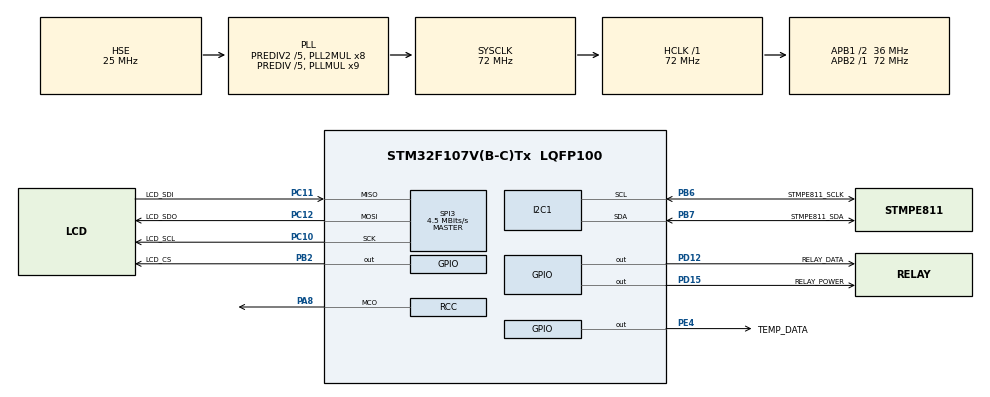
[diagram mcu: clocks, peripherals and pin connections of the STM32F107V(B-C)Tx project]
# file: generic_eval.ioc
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I2C1.I2C_Mode=I2C_Fast
Mcu.Family=STM32F1
Mcu.Name=STM32F107V(B-C)Tx
Mcu.Package=LQFP100
NVIC.PriorityGroup=NVIC_PRIORITYGROUP_4
NVIC.RTC_IRQn=true\:0\:0\:false\:false\:true\:true
NVIC.TIM2_IRQn=true\:5\:0\:true\:false\:true\:true
OSC_IN.Mode=HSE-External-Oscillator
OSC_IN.Signal=RCC_OSC_IN
OSC_OUT.Mode=HSE-External-Oscillator
OSC_OUT.Signal=RCC_OSC_OUT
PA13.Mode=Serial_Wire
PA13.Signal=SYS_JTMS-SWDIO
PA14.Mode=Serial_Wire
PA14.Signal=SYS_JTCK-SWCLK
PA8.Mode=Clock-out
PA8.Signal=RCC_MCO
PB2.GPIO_Label=LCD_CS
PB2.Signal=GPIO_Output
PB6.GPIO_Label=STMPE811_SCLK
PB6.GPIO_Speed=GPIO_SPEED_FREQ_LOW
PB6.Mode=I2C
PB6.Signal=I2C1_SCL
PB7.GPIO_Label=STMPE811_SDA
PB7.GPIO_Speed=GPIO_SPEED_FREQ_LOW
PB7.Mode=I2C
PB7.Signal=I2C1_SDA
PC10.GPIO_Label=LCD_SCL
PC10.Mode=Full_Duplex_Master
PC10.Signal=SPI3_SCK
PC11.GPIO_Label=LCD_SDI
PC11.Mode=Full_Duplex_Master
PC11.Signal=SPI3_MISO
PC12.GPIO_Label=LCD_SDO
PC12.Mode=Full_Duplex_Master
PC12.Signal=SPI3_MOSI
PC14-OSC32_IN.Mode=LSE-External-Oscillator
PC14-OSC32_IN.Signal=RCC_OSC32_IN
PC15-OSC32_OUT.Mode=LSE-External-Oscillator
PC15-OSC32_OUT.Signal=RCC_OSC32_OUT
PD12.GPIO_Label=RELAY_DATA
PD12.GPIO_Speed=GPIO_SPEED_FREQ_MEDIUM
PD12.Signal=GPIO_Output
PD15.GPIO_Label=RELAY_POWER
PD15.GPIO_Speed=GPIO_SPEED_FREQ_MEDIUM
PD15.PinState=GPIO_PIN_SET
PD15.Signal=GPIO_Output
PE4.GPIO_Label=TEMP_DATA
PE4.GPIO_ModeDefaultOutputPP=GPIO_MODE_OUTPUT_PP
PE4.GPIO_Speed=GPIO_SPEED_FREQ_MEDIUM
PE4.Signal=GPIO_Output
ProjectManager.HeapSize=0x200
ProjectManager.StackSize=0x400
ProjectManager.TargetToolchain=Makefile
RCC.AHBFreq_Value=72000000
RCC.APB1CLKDivider=RCC_HCLK_DIV2
RCC.APB1Freq_Value=36000000
RCC.APB1TimFreq_Value=72000000
RCC.APB2Freq_Value=72000000
RCC.APB2TimFreq_Value=72000000
RCC.HCLKFreq_Value=72000000
RCC.HSEDivPLL=RCC_HSE_PREDIV_DIV5
RCC.HSE_VALUE=25000000
RCC.PLLMUL=RCC_PLL_MUL9
RCC.PLLSourceVirtual=RCC_PLLSOURCE_HSE
RCC.Prediv1Source=RCC_PREDIV1_SOURCE_PLL2
RCC.Prediv2=RCC_HSE_PREDIV2_DIV5
RCC.RCC_MCOSource=RCC_MCO1SOURCE_HSE
RCC.RTCClockSelection=RCC_RTCCLKSOURCE_LSE
RCC.SYSCLKFreq_VALUE=72000000
RCC.SYSCLKSource=RCC_SYSCLKSOURCE_PLLCLK
RCC.USBFreq_Value=48000000
RTC.AutoPrediv=RTC_AUTO_1_SECOND
RTC.Format=RTC_FORMAT_BCD
RTC.OutPut=RTC_OUTPUTSOURCE_SECOND
SPI3.BaudRatePrescaler=SPI_BAUDRATEPRESCALER_8
SPI3.CLKPhase=SPI_PHASE_2EDGE
SPI3.CLKPolarity=SPI_POLARITY_HIGH
SPI3.CRCCalculation=SPI_CRCCALCULATION_DISABLE
SPI3.CalculateBaudRate=4.5 MBits/s
SPI3.Direction=SPI_DIRECTION_2LINES
SPI3.Mode=SPI_MODE_MASTER
SPI3.VirtualType=VM_MASTER
TIM2.Period=200
TIM2.Prescaler=36000
TIM2.TIM_MasterOutputTrigger=TIM_TRGO_RESET
VP_RTC_VS_RTC_Activate.Mode=RTC_Enabled
VP_TIM2_VS_ClockSourceINT.Mode=Internal
board=generic_eval

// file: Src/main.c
/**
  ******************************************************************************
  * @file           : main.c
  * @brief          : Main program body
  ******************************************************************************
  ** This notice applies to any and all portions of this file
  * that are not between comment pairs USER CODE BEGIN and
  * USER CODE END. Other portions of this file, whether
  * inserted by the user or by software development tools
  * are owned by their respective copyright owners.
  *
  * COPYRIGHT(c) 2018 STMicroelectronics
  *
  * Redistribution and use in source and binary forms, with or without modification,
  * are permitted provided that the following conditions are met:
  *   1. Redistributions of source code must retain the above copyright notice,
  *      this list of conditions and the following disclaimer.
  *   2. Redistributions in binary form must reproduce the above copyright notice,
  *      this list of conditions and the following disclaimer in the documentation
  *      and/or other materials provided with the distribution.
  *   3. Neither the name of STMicroelectronics nor the names of its contributors
  *      may be used to endorse or promote products derived from this software
  *      without specific prior written permission.
  *
  * THIS SOFTWARE IS PROVIDED BY THE COPYRIGHT HOLDERS AND CONTRIBUTORS "AS IS"
  * AND ANY EXPRESS OR IMPLIED WARRANTIES, INCLUDING, BUT NOT LIMITED TO, THE
  * IMPLIED WARRANTIES OF MERCHANTABILITY AND FITNESS FOR A PARTICULAR PURPOSE ARE
  * DISCLAIMED. IN NO EVENT SHALL THE COPYRIGHT HOLDER OR CONTRIBUTORS BE LIABLE
  * FOR ANY DIRECT, INDIRECT, INCIDENTAL, SPECIAL, EXEMPLARY, OR CONSEQUENTIAL
  * DAMAGES (INCLUDING, BUT NOT LIMITED TO, PROCUREMENT OF SUBSTITUTE GOODS OR
  * SERVICES; LOSS OF USE, DATA, OR PROFITS; OR BUSINESS INTERRUPTION) HOWEVER
  * CAUSED AND ON ANY THEORY OF LIABILITY, WHETHER IN CONTRACT, STRICT LIABILITY,
  * OR TORT (INCLUDING NEGLIGENCE OR OTHERWISE) ARISING IN ANY WAY OUT OF THE USE
  * OF THIS SOFTWARE, EVEN IF ADVISED OF THE POSSIBILITY OF SUCH DAMAGE.
  *
  ******************************************************************************
  */
#include "main.h"
#include "stm32f1xx_hal.h"

/* USER CODE BEGIN Includes */
#include "stm3210c_eval.h" // For BSP_LED_Init
/* USER CODE END Includes */

I2C_HandleTypeDef hi2c1;

RTC_HandleTypeDef hrtc;

SPI_HandleTypeDef hspi3;

TIM_HandleTypeDef htim2;

/* USER CODE BEGIN PV */
/* Private variables ---------------------------------------------------------*/

/* USER CODE END PV */

void SystemClock_Config(void);
static void MX_GPIO_Init(void);
static void MX_RTC_Init(void);
static void MX_I2C1_Init(void);
static void MX_SPI3_Init(void);
static void MX_TIM2_Init(void);

/* USER CODE BEGIN PFP */
/* Private function prototypes -----------------------------------------------*/

/* USER CODE END PFP */

/* USER CODE BEGIN 0 */
#if 0
/* USER CODE END 0 */

int main(void)
{
  /* USER CODE BEGIN 1 */
#endif
int cube_main(void)
{
  /* USER CODE END 1 */

  /* MCU Configuration----------------------------------------------------------*/

  /* Reset of all peripherals, Initializes the Flash interface and the Systick. */
  HAL_Init();

  /* Configure the system clock */
  SystemClock_Config();

  /* Initialize all configured peripherals */
  MX_GPIO_Init();
  MX_RTC_Init();
  MX_I2C1_Init();
  MX_SPI3_Init();
  MX_TIM2_Init();
  /* USER CODE BEGIN 2 */
  HAL_RTCEx_SetSecond_IT(&hrtc);
  /* USER CODE END 2 */

  /* Infinite loop */

}

void SystemClock_Config(void)
{

  RCC_OscInitTypeDef RCC_OscInitStruct;
  RCC_ClkInitTypeDef RCC_ClkInitStruct;
  RCC_PeriphCLKInitTypeDef PeriphClkInit;

    /**Initializes the CPU, AHB and APB busses clocks
    */
  RCC_OscInitStruct.OscillatorType = RCC_OSCILLATORTYPE_HSE|RCC_OSCILLATORTYPE_LSE;
  RCC_OscInitStruct.HSEState = RCC_HSE_ON;
  RCC_OscInitStruct.HSEPredivValue = RCC_HSE_PREDIV_DIV5;
  RCC_OscInitStruct.LSEState = RCC_LSE_ON;
  RCC_OscInitStruct.HSIState = RCC_HSI_ON;
  RCC_OscInitStruct.Prediv1Source = RCC_PREDIV1_SOURCE_PLL2;
  RCC_OscInitStruct.PLL.PLLState = RCC_PLL_ON;
  RCC_OscInitStruct.PLL.PLLSource = RCC_PLLSOURCE_HSE;
  RCC_OscInitStruct.PLL.PLLMUL = RCC_PLL_MUL9;
  RCC_OscInitStruct.PLL2.PLL2State = RCC_PLL2_ON;
  RCC_OscInitStruct.PLL2.PLL2MUL = RCC_PLL2_MUL8;
  RCC_OscInitStruct.PLL2.HSEPrediv2Value = RCC_HSE_PREDIV2_DIV5;
  if (HAL_RCC_OscConfig(&RCC_OscInitStruct) != HAL_OK)
  {
    _Error_Handler(__FILE__, __LINE__);
  }

    /**Initializes the CPU, AHB and APB busses clocks
    */
  RCC_ClkInitStruct.ClockType = RCC_CLOCKTYPE_HCLK|RCC_CLOCKTYPE_SYSCLK
                              |RCC_CLOCKTYPE_PCLK1|RCC_CLOCKTYPE_PCLK2;
  RCC_ClkInitStruct.SYSCLKSource = RCC_SYSCLKSOURCE_PLLCLK;
  RCC_ClkInitStruct.AHBCLKDivider = RCC_SYSCLK_DIV1;
  RCC_ClkInitStruct.APB1CLKDivider = RCC_HCLK_DIV2;
  RCC_ClkInitStruct.APB2CLKDivider = RCC_HCLK_DIV1;

  if (HAL_RCC_ClockConfig(&RCC_ClkInitStruct, FLASH_LATENCY_2) != HAL_OK)
  {
    _Error_Handler(__FILE__, __LINE__);
  }

  PeriphClkInit.PeriphClockSelection = RCC_PERIPHCLK_RTC;
  PeriphClkInit.RTCClockSelection = RCC_RTCCLKSOURCE_LSE;
  if (HAL_RCCEx_PeriphCLKConfig(&PeriphClkInit) != HAL_OK)
  {
    _Error_Handler(__FILE__, __LINE__);
  }

  HAL_RCC_MCOConfig(RCC_MCO, RCC_MCO1SOURCE_HSE, RCC_MCODIV_1);

    /**Configure the Systick interrupt time
    */
  HAL_SYSTICK_Config(HAL_RCC_GetHCLKFreq()/1000);

    /**Configure the Systick
    */
  HAL_SYSTICK_CLKSourceConfig(SYSTICK_CLKSOURCE_HCLK);

    /**Configure the Systick interrupt time
    */
  __HAL_RCC_PLLI2S_ENABLE();

  /* SysTick_IRQn interrupt configuration */
  HAL_NVIC_SetPriority(SysTick_IRQn, 0, 0);
}

/* I2C1 init function */
static void MX_I2C1_Init(void)
{

  hi2c1.Instance = I2C1;
  hi2c1.Init.ClockSpeed = 400000;
  hi2c1.Init.DutyCycle = I2C_DUTYCYCLE_2;
  hi2c1.Init.OwnAddress1 = 0;
  hi2c1.Init.AddressingMode = I2C_ADDRESSINGMODE_7BIT;
  hi2c1.Init.DualAddressMode = I2C_DUALADDRESS_DISABLE;
  hi2c1.Init.OwnAddress2 = 0;
  hi2c1.Init.GeneralCallMode = I2C_GENERALCALL_DISABLE;
  hi2c1.Init.NoStretchMode = I2C_NOSTRETCH_DISABLE;
  if (HAL_I2C_Init(&hi2c1) != HAL_OK)
  {
    _Error_Handler(__FILE__, __LINE__);
  }

}

/* RTC init function */
static void MX_RTC_Init(void)
{

    /**Initialize RTC Only
    */
  hrtc.Instance = RTC;
  hrtc.Init.AsynchPrediv = RTC_AUTO_1_SECOND;
  hrtc.Init.OutPut = RTC_OUTPUTSOURCE_SECOND;
  if (HAL_RTC_Init(&hrtc) != HAL_OK)
  {
    _Error_Handler(__FILE__, __LINE__);
  }

}

/* SPI3 init function */
static void MX_SPI3_Init(void)
{

  /* SPI3 parameter configuration*/
  hspi3.Instance = SPI3;
  hspi3.Init.Mode = SPI_MODE_MASTER;
  hspi3.Init.Direction = SPI_DIRECTION_2LINES;
  hspi3.Init.DataSize = SPI_DATASIZE_8BIT;
  hspi3.Init.CLKPolarity = SPI_POLARITY_HIGH;
  hspi3.Init.CLKPhase = SPI_PHASE_2EDGE;
  hspi3.Init.NSS = SPI_NSS_SOFT;
  hspi3.Init.BaudRatePrescaler = SPI_BAUDRATEPRESCALER_8;
  hspi3.Init.FirstBit = SPI_FIRSTBIT_MSB;
  hspi3.Init.TIMode = SPI_TIMODE_DISABLE;
  hspi3.Init.CRCCalculation = SPI_CRCCALCULATION_DISABLE;
  hspi3.Init.CRCPolynomial = 10;
  if (HAL_SPI_Init(&hspi3) != HAL_OK)
  {
    _Error_Handler(__FILE__, __LINE__);
  }

}

/* TIM2 init function */
static void MX_TIM2_Init(void)
{

  TIM_ClockConfigTypeDef sClockSourceConfig;
  TIM_MasterConfigTypeDef sMasterConfig;

  htim2.Instance = TIM2;
  htim2.Init.Prescaler = 36000;
  htim2.Init.CounterMode = TIM_COUNTERMODE_UP;
  htim2.Init.Period = 200;
  htim2.Init.ClockDivision = TIM_CLOCKDIVISION_DIV1;
  //htim2.Init.AutoReloadPreload = TIM_AUTORELOAD_PRELOAD_DISABLE;
  if (HAL_TIM_Base_Init(&htim2) != HAL_OK)
  {
    _Error_Handler(__FILE__, __LINE__);
  }

  sClockSourceConfig.ClockSource = TIM_CLOCKSOURCE_INTERNAL;
  if (HAL_TIM_ConfigClockSource(&htim2, &sClockSourceConfig) != HAL_OK)
  {
    _Error_Handler(__FILE__, __LINE__);
  }

  sMasterConfig.MasterOutputTrigger = TIM_TRGO_RESET;
  sMasterConfig.MasterSlaveMode = TIM_MASTERSLAVEMODE_DISABLE;
  if (HAL_TIMEx_MasterConfigSynchronization(&htim2, &sMasterConfig) != HAL_OK)
  {
    _Error_Handler(__FILE__, __LINE__);
  }

}

/** Configure pins as
        * Analog
        * Input
        * Output
        * EVENT_OUT
        * EXTI
     PA8   ------> RCC_MCO
*/
static void MX_GPIO_Init(void)
{

  GPIO_InitTypeDef GPIO_InitStruct;

  /* GPIO Ports Clock Enable */
  __HAL_RCC_GPIOE_CLK_ENABLE();
  __HAL_RCC_GPIOC_CLK_ENABLE();
  __HAL_RCC_GPIOA_CLK_ENABLE();
  __HAL_RCC_GPIOB_CLK_ENABLE();
  __HAL_RCC_GPIOD_CLK_ENABLE();

  /*Configure GPIO pin Output Level */
  HAL_GPIO_WritePin(TEMP_DATA_GPIO_Port, TEMP_DATA_Pin, GPIO_PIN_RESET);

  /*Configure GPIO pin Output Level */
  HAL_GPIO_WritePin(LCD_CS_GPIO_Port, LCD_CS_Pin, GPIO_PIN_RESET);

  /*Configure GPIO pin Output Level */
  HAL_GPIO_WritePin(RELAY_DATA_GPIO_Port, RELAY_DATA_Pin, GPIO_PIN_RESET);

  /*Configure GPIO pin Output Level */
  HAL_GPIO_WritePin(RELAY_POWER_GPIO_Port, RELAY_POWER_Pin, GPIO_PIN_SET);

  /*Configure GPIO pin : TEMP_DATA_Pin */
  GPIO_InitStruct.Pin = TEMP_DATA_Pin;
  GPIO_InitStruct.Mode = GPIO_MODE_OUTPUT_PP;
  GPIO_InitStruct.Speed = GPIO_SPEED_FREQ_MEDIUM;
  HAL_GPIO_Init(TEMP_DATA_GPIO_Port, &GPIO_InitStruct);

  /*Configure GPIO pin : LCD_CS_Pin */
  GPIO_InitStruct.Pin = LCD_CS_Pin;
  GPIO_InitStruct.Mode = GPIO_MODE_OUTPUT_PP;
  GPIO_InitStruct.Speed = GPIO_SPEED_FREQ_LOW;
  HAL_GPIO_Init(LCD_CS_GPIO_Port, &GPIO_InitStruct);

  /*Configure GPIO pins : RELAY_DATA_Pin RELAY_POWER_Pin */
  GPIO_InitStruct.Pin = RELAY_DATA_Pin|RELAY_POWER_Pin;
  GPIO_InitStruct.Mode = GPIO_MODE_OUTPUT_PP;
  GPIO_InitStruct.Speed = GPIO_SPEED_FREQ_MEDIUM;
  HAL_GPIO_Init(GPIOD, &GPIO_InitStruct);

  /*Configure GPIO pin : PA8 */
  GPIO_InitStruct.Pin = GPIO_PIN_8;
  GPIO_InitStruct.Mode = GPIO_MODE_AF_PP;
  GPIO_InitStruct.Speed = GPIO_SPEED_FREQ_LOW;
  HAL_GPIO_Init(GPIOA, &GPIO_InitStruct);

}

void _Error_Handler(const char *file, int line)
{
  /* USER CODE BEGIN Error_Handler_Debug */
  /* User can add his own implementation to report the HAL error return state */
  BSP_LED_Init(LED_ORANGE);
  while(1)
  {
    BSP_LED_Toggle(LED_ORANGE);
    HAL_Delay(500);
  }
  /* USER CODE END Error_Handler_Debug */
}

/************************ (C) COPYRIGHT STMicroelectronics *****END OF FILE****/
